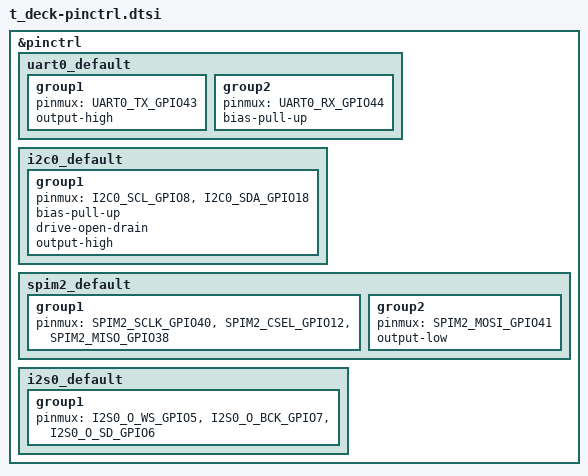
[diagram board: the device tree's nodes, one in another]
/*
 * SPDX-FileCopyrightText: Copyright The Zephyr Project Contributors
 * SPDX-License-Identifier: Apache-2.0
 */

#include <zephyr/dt-bindings/pinctrl/esp-pinctrl-common.h>
#include <zephyr/dt-bindings/pinctrl/esp32s3-pinctrl.h>
#include <zephyr/dt-bindings/pinctrl/esp32s3-gpio-sigmap.h>

&pinctrl {
	uart0_default: uart0_default {
		group1 {
			pinmux = <UART0_TX_GPIO43>;
			output-high;
		};

		group2 {
			pinmux = <UART0_RX_GPIO44>;
			bias-pull-up;
		};
	};

	i2c0_default: i2c0_default {
		group1 {
			pinmux = <I2C0_SCL_GPIO8>, <I2C0_SDA_GPIO18>;
			bias-pull-up;
			drive-open-drain;
			output-high;
		};
	};

	spim2_default: spim2_default {
		group1 {
			pinmux = <SPIM2_SCLK_GPIO40>, <SPIM2_CSEL_GPIO12>, <SPIM2_MISO_GPIO38>;
		};

		group2 {
			pinmux = <SPIM2_MOSI_GPIO41>;
			output-low;
		};
	};

	i2s0_default: i2s0_default {
		group1 {
			pinmux = <I2S0_O_WS_GPIO5>,
				 <I2S0_O_BCK_GPIO7>,
				 <I2S0_O_SD_GPIO6>;
		};
	};
};
